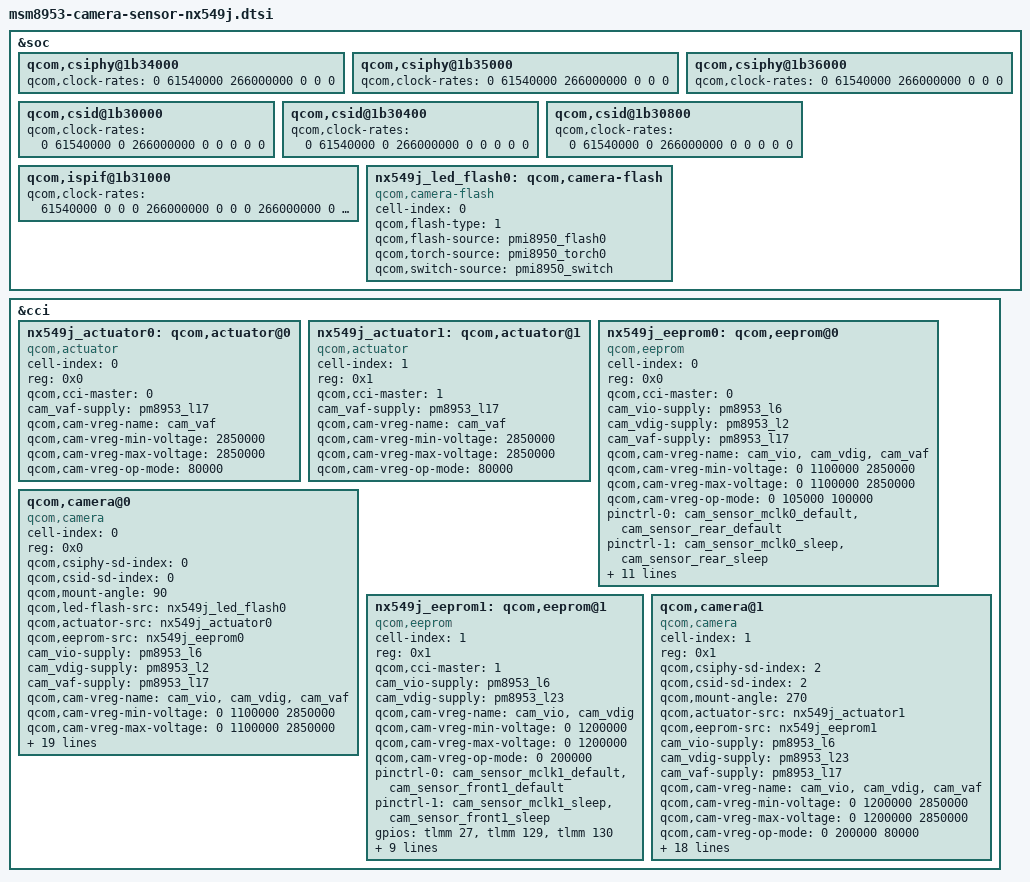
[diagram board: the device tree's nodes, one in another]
/*
 * Nubia NX549J camera wiring.
 *
 * PROPER-FIX: replace the generic MSM8953 MTP camera sensor graph with the
 * stock NX549J 3.18 GPIO/regulator layout.
 */

&soc {
	/delete-node/ qcom,camera-flash;

	qcom,csiphy@1b34000 {
		qcom,clock-rates = <0 61540000 266000000 0 0 0>;
	};

	qcom,csiphy@1b35000 {
		qcom,clock-rates = <0 61540000 266000000 0 0 0>;
	};

	qcom,csiphy@1b36000 {
		qcom,clock-rates = <0 61540000 266000000 0 0 0>;
	};

	qcom,csid@1b30000  {
		qcom,clock-rates = <0 61540000 0 266000000 0 0 0 0 0>;
	};

	qcom,csid@1b30400 {
		qcom,clock-rates = <0 61540000 0 266000000 0 0 0 0 0>;
	};

	qcom,csid@1b30800 {
		qcom,clock-rates = <0 61540000 0 266000000 0 0 0 0 0>;
	};

	qcom,ispif@1b31000 {
		qcom,clock-rates = <61540000 0 0 0
			266000000 0 0 0
			266000000 0 0 0
			266000000 0 0 0
			0 0 0
			0 0 0>;
	};

	nx549j_led_flash0: qcom,camera-flash {
		cell-index = <0>;
		compatible = "qcom,camera-flash";
		qcom,flash-type = <1>;
		qcom,flash-source = <&pmi8950_flash0>;
		qcom,torch-source = <&pmi8950_torch0>;
		qcom,switch-source = <&pmi8950_switch>;
	};

};

&cci {
	#address-cells = <1>;
	#size-cells = <0>;

	/delete-node/ qcom,actuator@0;
	/delete-node/ qcom,actuator@1;
	/delete-node/ qcom,eeprom@0;
	/delete-node/ qcom,eeprom@1;
	/delete-node/ qcom,eeprom@2;
	/delete-node/ qcom,camera@0;
	/delete-node/ qcom,camera@1;
	/delete-node/ qcom,camera@2;

	nx549j_actuator0: qcom,actuator@0 {
		cell-index = <0>;
		reg = <0x0>;
		compatible = "qcom,actuator";
		qcom,cci-master = <0>;
		cam_vaf-supply = <&pm8953_l17>;
		qcom,cam-vreg-name = "cam_vaf";
		qcom,cam-vreg-min-voltage = <2850000>;
		qcom,cam-vreg-max-voltage = <2850000>;
		qcom,cam-vreg-op-mode = <80000>;
	};

	nx549j_actuator1: qcom,actuator@1 {
		cell-index = <1>;
		reg = <0x1>;
		compatible = "qcom,actuator";
		qcom,cci-master = <1>;
		cam_vaf-supply = <&pm8953_l17>;
		qcom,cam-vreg-name = "cam_vaf";
		qcom,cam-vreg-min-voltage = <2850000>;
		qcom,cam-vreg-max-voltage = <2850000>;
		qcom,cam-vreg-op-mode = <80000>;
	};

	nx549j_eeprom0: qcom,eeprom@0 {
		cell-index = <0>;
		reg = <0x0>;
		qcom,cci-master = <0>;
		compatible = "qcom,eeprom";
		cam_vio-supply = <&pm8953_l6>;
		cam_vdig-supply = <&pm8953_l2>;
		cam_vaf-supply = <&pm8953_l17>;
		qcom,cam-vreg-name = "cam_vio", "cam_vdig", "cam_vaf";
		qcom,cam-vreg-min-voltage = <0 1100000 2850000>;
		qcom,cam-vreg-max-voltage = <0 1100000 2850000>;
		qcom,cam-vreg-op-mode = <0 105000 100000>;

		pinctrl-names = "cam_default", "cam_suspend";
		pinctrl-0 = <&cam_sensor_mclk0_default
				&cam_sensor_rear_default>;
		pinctrl-1 = <&cam_sensor_mclk0_sleep
				&cam_sensor_rear_sleep>;
		gpios = <&tlmm 26 0>,
			<&tlmm 40 0>,
			<&tlmm 39 0>,
			<&tlmm 13 0>;
		qcom,gpio-reset = <1>;
		qcom,gpio-standby = <2>;
		qcom,gpio-vana = <3>;
		qcom,gpio-req-tbl-num = <0 1 2 3>;
		qcom,gpio-req-tbl-flags = <1 0 0 0>;
		qcom,gpio-req-tbl-label = "CAMIF_MCLK0",
			"CAM_RESET0",
			"CAM_STANDBY0",
			"CAM_VANA0";

		status = "ok";
		clocks = <&clock_gcc clk_mclk0_clk_src>,
			<&clock_gcc clk_gcc_camss_mclk0_clk>;
		clock-names = "cam_src_clk", "cam_clk";
		qcom,clock-rates = <24000000 0>;
	};

	qcom,camera@0 {
		cell-index = <0>;
		compatible = "qcom,camera";
		reg = <0x0>;
		qcom,csiphy-sd-index = <0>;
		qcom,csid-sd-index = <0>;
		qcom,mount-angle = <90>;
		qcom,led-flash-src = <&nx549j_led_flash0>;
		qcom,actuator-src = <&nx549j_actuator0>;
		qcom,eeprom-src = <&nx549j_eeprom0>;
		cam_vio-supply = <&pm8953_l6>;
		cam_vdig-supply = <&pm8953_l2>;
		cam_vaf-supply = <&pm8953_l17>;
		qcom,cam-vreg-name = "cam_vio", "cam_vdig", "cam_vaf";
		qcom,cam-vreg-min-voltage = <0 1100000 2850000>;
		qcom,cam-vreg-max-voltage = <0 1100000 2850000>;
		qcom,cam-vreg-op-mode = <0 105000 100000>;
		pinctrl-names = "cam_default", "cam_suspend";
		pinctrl-0 = <&cam_sensor_mclk0_default &cam_sensor_rear_default>;
		pinctrl-1 = <&cam_sensor_mclk0_sleep &cam_sensor_rear_sleep>;
		gpios = <&tlmm 26 0>,
			<&tlmm 40 0>,
			<&tlmm 39 0>,
			<&tlmm 13 0>;
		qcom,gpio-reset = <1>;
		qcom,gpio-standby = <2>;
		qcom,gpio-vana = <3>;
		qcom,gpio-req-tbl-num = <0 1 2 3>;
		qcom,gpio-req-tbl-flags = <1 0 0 0>;
		qcom,gpio-req-tbl-label = "CAMIF_MCLK0",
			"CAM_RESET0",
			"CAM_STANDBY0",
			"CAM_VANA0";
		qcom,sensor-position = <0>;
		qcom,sensor-mode = <0>;
		qcom,cci-master = <0>;
		status = "ok";
		clocks = <&clock_gcc clk_mclk0_clk_src>,
			<&clock_gcc clk_gcc_camss_mclk0_clk>;
		clock-names = "cam_src_clk", "cam_clk";
		qcom,clock-rates = <24000000 0>;
	};

	nx549j_eeprom1: qcom,eeprom@1 {
		cell-index = <1>;
		reg = <0x1>;
		qcom,cci-master = <1>;
		compatible = "qcom,eeprom";
		cam_vio-supply = <&pm8953_l6>;
		cam_vdig-supply = <&pm8953_l23>;
		qcom,cam-vreg-name = "cam_vio", "cam_vdig";
		qcom,cam-vreg-min-voltage = <0 1200000>;
		qcom,cam-vreg-max-voltage = <0 1200000>;
		qcom,cam-vreg-op-mode = <0 200000>;

		pinctrl-names = "cam_default", "cam_suspend";
		pinctrl-0 = <&cam_sensor_mclk1_default
				&cam_sensor_front1_default>;
		pinctrl-1 = <&cam_sensor_mclk1_sleep
				&cam_sensor_front1_sleep>;
		gpios = <&tlmm 27 0>,
			<&tlmm 129 0>,
			<&tlmm 130 0>;
		qcom,gpio-reset = <1>;
		qcom,gpio-standby = <2>;
		qcom,gpio-req-tbl-num = <0 1 2>;
		qcom,gpio-req-tbl-flags = <1 0 0>;
		qcom,gpio-req-tbl-label = "CAMIF_MCLK1",
			"CAM_RESET1",
			"CAM_STANDBY1";

		status = "ok";
		clocks = <&clock_gcc clk_mclk1_clk_src>,
			<&clock_gcc clk_gcc_camss_mclk1_clk>;
		clock-names = "cam_src_clk", "cam_clk";
		qcom,clock-rates = <24000000 0>;
	};

	qcom,camera@1 {
		cell-index = <1>;
		compatible = "qcom,camera";
		reg = <0x1>;
		qcom,csiphy-sd-index = <2>;
		qcom,csid-sd-index = <2>;
		qcom,mount-angle = <270>;
		qcom,actuator-src = <&nx549j_actuator1>;
		qcom,eeprom-src = <&nx549j_eeprom1>;
		cam_vio-supply = <&pm8953_l6>;
		cam_vdig-supply = <&pm8953_l23>;
		cam_vaf-supply = <&pm8953_l17>;
		qcom,cam-vreg-name = "cam_vio", "cam_vdig", "cam_vaf";
		qcom,cam-vreg-min-voltage = <0 1200000 2850000>;
		qcom,cam-vreg-max-voltage = <0 1200000 2850000>;
		qcom,cam-vreg-op-mode = <0 200000 80000>;
		pinctrl-names = "cam_default", "cam_suspend";
		pinctrl-0 = <&cam_sensor_mclk1_default
				&cam_sensor_front1_default>;
		pinctrl-1 = <&cam_sensor_mclk1_sleep
				&cam_sensor_front1_sleep>;
		gpios = <&tlmm 27 0>,
			<&tlmm 129 0>,
			<&tlmm 130 0>,
			<&tlmm 13 0>;
		qcom,gpio-reset = <1>;
		qcom,gpio-standby = <2>;
		qcom,gpio-vana = <3>;
		qcom,gpio-req-tbl-num = <0 1 2 3>;
		qcom,gpio-req-tbl-flags = <1 0 0 0>;
		qcom,gpio-req-tbl-label = "CAMIF_MCLK1",
			"CAM_RESET1",
			"CAM_STANDBY1",
			"CAM_VANA1";
		qcom,sensor-position = <1>;
		qcom,sensor-mode = <1>;
		qcom,cci-master = <1>;
		status = "ok";
		clocks = <&clock_gcc clk_mclk1_clk_src>,
			<&clock_gcc clk_gcc_camss_mclk1_clk>;
		clock-names = "cam_src_clk", "cam_clk";
		qcom,clock-rates = <24000000 0>;
	};
};
